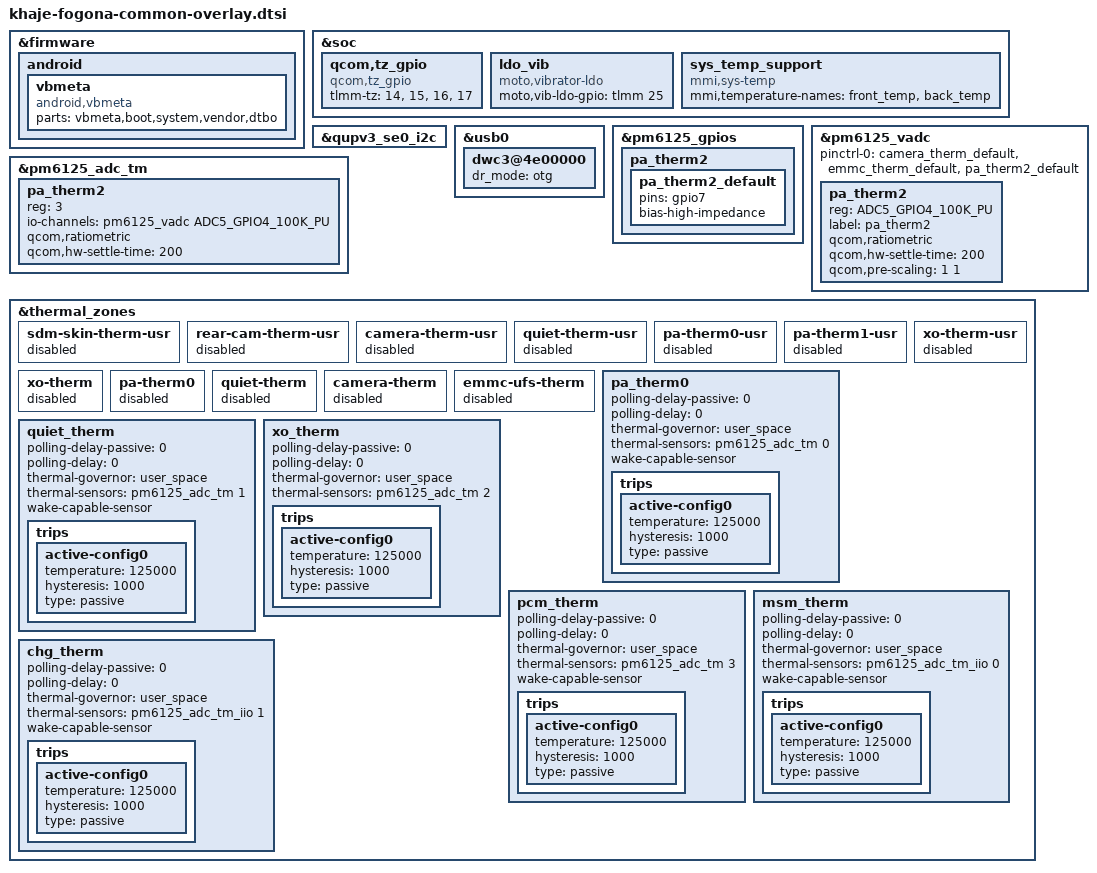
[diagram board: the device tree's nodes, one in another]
/* Copyright (c) 2019, The Linux Foundation. All rights reserved.
 *
 * This program is free software; you can redistribute it and/or modify
 * it under the terms of the GNU General Public License version 2 and
 * only version 2 as published by the Free Software Foundation.
 *
 * This program is distributed in the hope that it will be useful,
 * but WITHOUT ANY WARRANTY; without even the implied warranty of
 * MERCHANTABILITY or FITNESS FOR A PARTICULAR PURPOSE.  See the
 * GNU General Public License for more details.
 */

#include <dt-bindings/interrupt-controller/arm-gic.h>

#include <dt-bindings/gpio/gpio.h>
#include <dt-bindings/iio/qcom,spmi-vadc.h>
#include <dt-bindings/input/input.h>
#include <dt-bindings/clock/qcom,gcc-khaje.h>


#include "khaje-moto-common-overlay.dtsi"

#include "sgm7220.dtsi"
#include "discrete_charging.dtsi"
#include "discrete-rt-pd-manger.dtsi"

#include "khaje-fogona-sar-sensor-overlay.dtsi"

#include "khaje-fogona-fps-overlay.dtsi"
&firmware {
	android {
		vbmeta {
			compatible = "android,vbmeta";
			parts = "vbmeta,boot,system,vendor,dtbo";
		};
	};
};


&soc {
    qcom,tz_gpio {
        compatible = "qcom,tz_gpio";
        tlmm-tz = <14>,
                        <15>,
                        <16>,
                        <17>;
    };

	ldo_vib {
		compatible = "moto,vibrator-ldo";
		moto,vib-ldo-gpio = <&tlmm 25 0x0>;
		status = "ok";
	};
};



&qupv3_se0_i2c {
        status = "ok";
};

&usb0 {
	dwc3@4e00000 {
		dr_mode = "otg";
	};
};




&soc {
        sys_temp_support {
                compatible = "mmi,sys-temp";
                mmi,temperature-names = "front_temp",
                        "back_temp";
                status = "ok";
        };
};

&pm6125_gpios {
	pa_therm2 {
		pa_therm2_default: pa_therm2_default {
			pins = "gpio7";
			bias-high-impedance;
		};
	};
};

&pm6125_vadc {
	pinctrl-0 = <&camera_therm_default &emmc_therm_default &pa_therm2_default>;

	pa_therm2 {
		reg = <ADC5_GPIO4_100K_PU>;
		label = "pa_therm2";
		qcom,ratiometric;
		qcom,hw-settle-time = <200>;
		qcom,pre-scaling = <1 1>;
	};
};

&pm6125_adc_tm {
	pa_therm2 {
		reg = <3>;
		io-channels = <&pm6125_vadc ADC5_GPIO4_100K_PU>;
		qcom,ratiometric;
		qcom,hw-settle-time = <200>;
	};
};

&thermal_zones {
	sdm-skin-therm-usr {
		status = "disabled";
	};
	rear-cam-therm-usr {
		status = "disabled";
	};
	camera-therm-usr {
		status = "disabled";
	};
	quiet-therm-usr {
		status = "disabled";
	};
	pa-therm0-usr {
		status = "disabled";
	};
	pa-therm1-usr {
		status = "disabled";
	};
	xo-therm-usr {
		status = "disabled";
	};

	xo-therm {
		status = "disabled";
	};

	pa-therm0 {
		status = "disabled";
	};

	quiet-therm {
		status = "disabled";
	};

	camera-therm {
		status = "disabled";
	};

	emmc-ufs-therm {
		status = "disabled";
	};

	pa_therm0 {
		polling-delay-passive = <0>;
		polling-delay = <0>;
		thermal-governor = "user_space";
		thermal-sensors = <&pm6125_adc_tm 0>;
		wake-capable-sensor;
		trips {
			active-config0 {
				temperature = <125000>;
				hysteresis = <1000>;
				type = "passive";
			};
		};
	};

	quiet_therm {
                polling-delay-passive = <0>;
                polling-delay = <0>;
                thermal-governor = "user_space";
                thermal-sensors = <&pm6125_adc_tm 1>;
                wake-capable-sensor;
                trips {
                        active-config0 {
                                temperature = <125000>;
                                hysteresis = <1000>;
                                type = "passive";
                        };
                };
        };

	xo_therm {
		polling-delay-passive = <0>;
		polling-delay = <0>;
		thermal-governor = "user_space";
		thermal-sensors = <&pm6125_adc_tm 2>;
		trips {
			active-config0 {
				temperature = <125000>;
				hysteresis = <1000>;
				type = "passive";
			};
		};
	};

	pcm_therm {
                polling-delay-passive = <0>;
                polling-delay = <0>;
                thermal-governor = "user_space";
                thermal-sensors = <&pm6125_adc_tm 3>;
                wake-capable-sensor;
                trips {
                        active-config0 {
                                temperature = <125000>;
                                hysteresis = <1000>;
                                type = "passive";
                        };
                };
        };

	msm_therm {
		polling-delay-passive = <0>;
		polling-delay = <0>;
		thermal-governor = "user_space";
		thermal-sensors = <&pm6125_adc_tm_iio 0>;
		wake-capable-sensor;
		trips {
			active-config0 {
				temperature = <125000>;
				hysteresis = <1000>;
				type = "passive";
			};
		};
	};

	chg_therm  {
		polling-delay-passive = <0>;
		polling-delay = <0>;
		thermal-governor = "user_space";
		thermal-sensors = <&pm6125_adc_tm_iio 1>;
		wake-capable-sensor;
		trips {
			active-config0 {
				temperature = <125000>;
				hysteresis = <1000>;
				type = "passive";
			};
		};
	};


};
